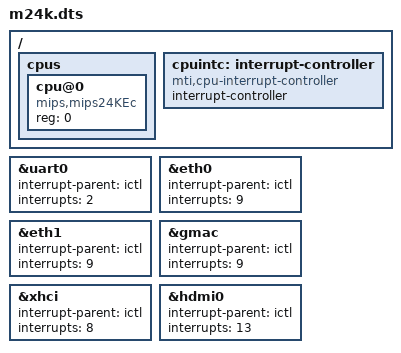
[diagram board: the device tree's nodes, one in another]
/*
 * Realtek Semiconductor Corp.
 *
 * Device Tree Structure
 *
 * Tony Wu (tonywu@realtek.com)
 */

/dts-v1/;

#include "sheipa.dtsi"

/ {
	#address-cells = <1>;
	#size-cells = <1>;

	cpus {
		#address-cells = <1>;
		#size-cells = <0>;

		cpu@0 {
			compatible = "mips,mips24KEc";
			device_type = "cpu";
			reg = <0>;
		};
	};

	cpuintc: interrupt-controller {
		#address-cells = <0>;
		#interrupt-cells = <1>;
		interrupt-controller;
		compatible = "mti,cpu-interrupt-controller";
	};

};

&uart0 {
	interrupt-parent = <&ictl>;
	interrupts = <2>;
};

&eth0 {
	interrupt-parent = <&ictl>;
	interrupts = <9>;
};

&eth1 {
	interrupt-parent = <&ictl>;
	interrupts = <9>;
};

&gmac {
	interrupt-parent = <&ictl>;
	interrupts = <9>;
};

&xhci {
	interrupt-parent = <&ictl>;
	interrupts = <8>;
};

&hdmi0 {
	interrupt-parent = <&ictl>;
	interrupts = <13>;
};
